# S32R372 register map
Vendor: Freescale Semiconductor, Inc.; Series: Qorivva; File version: 1.6
Registers are 32-bit, read-write, reset 0x0 unless marked. A register's access mark holds for its fields unless they carry their own. Offsets are from the block's base; [hi:lo] are bit positions; {n}, {i} and the like mark numbered series.

## SWT_1 — SWT
Base 0xFC054000; register names take the prefix SWT_1_
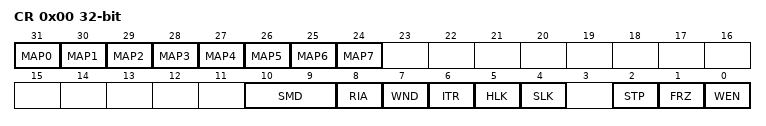
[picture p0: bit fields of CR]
0x00 CR — SWT Control Register
  [31-n] MAP{n} (n=0..7) — Master Access Protection for Master {n}
    0=Access for the master is not enabled; 1=Access for the master is enabled
  [10:9] SMD — Service Mode
    0=Fixed Service Sequence: The watchdog is serviced by writing the fixed sequence 0xA602, 0xB480 to SWT_SR; 1=Keyed Service Sequence: The watchdog is serviced by writing two pseudorandom key values to SWT_SR; 2=Fixed Address Execution: The watchdog is serviced by executing code at the address loaded into the designated IAC register, which cannot be updated while the watchdog is enabled; 3=Incremental Address Execution: The watchdog is serviced by executing code at the address loaded into the designated IAC register, which can be updated
  [8] RIA — Reset on Invalid Access
    0=Invalid access to the SWT generates a bus error; 1=Invalid access to the SWT causes a reset request if WEN is 1
  [7] WND — Window Mode
    0=Regular mode: service sequence can be done at any time; 1=Windowed mode: service sequence is valid only when the down counter is less than the value in the SWT_WN register
  [6] ITR — Interrupt Then Reset
    0=Generate a reset request on a time-out; 1=Generate an interrupt on an initial time-out; generate a reset request on a second consecutive time-out
  [5] HLK — Hard Lock
    0=SWT_CR, SWT_TO, SWT_WN and SWT_SK are read/write registers if SLK is 0; 1=SWT_CR, SWT_TO, SWT_WN and SWT_SK are read-only registers
  [4] SLK — Soft Lock
    0=SWT_CR, SWT_TO, SWT_WN and SWT_SK are read/write registers if HLK is 0; 1=SWT_CR, SWT_TO, SWT_WN and SWT_SK are read-only registers
  [2] STP — Stop Mode Control
    0=SWT counter continues to run in stop mode; 1=SWT counter is stopped in stop mode
  [1] FRZ — Debug Mode Control
    0=SWT counter continues to run in debug mode; 1=SWT counter is stopped in debug mode
  [0] WEN — Watchdog Enabled
    0=SWT is disabled; 1=SWT is enabled
0x04 IR — SWT Interrupt Register
  [0] TIF — Time-out Interrupt Flag
    0=No interrupt request; 1=Interrupt request due to an initial time-out
0x08 TO — SWT Time-out Register
  [31:0] WTO — Watchdog time-out period in clock cycles
0x0C WN — SWT Window Register
  [31:0] WST — Window Start Value
0x10 SR — SWT Service Register
  [15:0] WSC wo — Watchdog Service Code
0x14 CO ro — SWT Counter Output Register
  [31:0] CNT — Watchdog Count
0x18 SK — SWT Service Key Register
  [15:0] SK — Service Key

## SWT_2 — SWT
Base 0xFC058000; register names take the prefix SWT_2_
Registers as SWT_1.

## STM_1 — STM
Base 0xFC06C000; register names take the prefix STM_1_
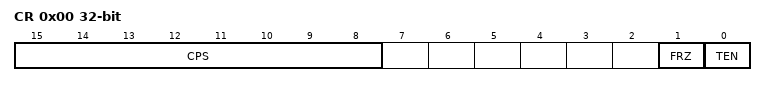
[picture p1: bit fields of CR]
0x00 CR — STM Control Register
  [15:8] CPS — Counter Prescaler.
  [1] FRZ — Freeze.
    0=STM counter continues to run in debug mode; 1=STM counter is stopped in debug mode
  [0] TEN — Timer counter Enabled.
    0=Counter is disabled; 1=Counter is enabled
0x04 CNT — STM Count Register
  [31:0] CNT — Timer count value used as the time base for all channels.
{0x10+0x10*i} CCR{i} (i=0..3) — STM Channel Control Register
  [0] CEN — Channel Enable
    0=The channel is disabled; 1=The channel is enabled
{0x14+0x10*i} CIR{i} (i=0..3) — STM Channel Interrupt Register
  [0] CIF — Channel Interrupt Flag
    0=No interrupt request; 1=Interrupt request due to a match on the channel
{0x18+0x10*i} CMP{i} (i=0..3) — STM Channel Compare Register
  [31:0] CMP — Compare value for channel n.

## STM_2 — STM
Base 0xFC070000; register names take the prefix STM_2_
Registers as STM_1.

## CSE
Base 0xFC074000; register names take the prefix CSE_
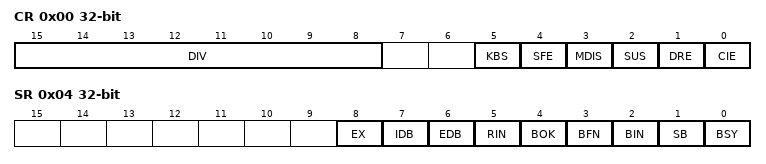
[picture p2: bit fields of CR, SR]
0x00 CR — CSE Control Register
  [15:8] DIV — TRNG Clock Divider Select
  [5] KBS — Key Bank Select. Selects which set of application keys are visible for commands. See .
    0=Select KEY_1-KEY_10; 1=Select KEY_11-KEY_20
  [4] SFE — Security Flag Extension
    0=Security Flag Extension disabled; 1=Security Flag Extension enabled
  [3] MDIS — Module Disable
    0=Normal mode; 1=Low-power mode
  [2] SUS — Suspend Command Processing
    0=Enable processing of commands; 1=Suspend command processing
  [1] DRE — DMA Request Enable
    0=DMA request not enabled; 1=DMA request enabled
  [0] CIE — Command Complete Interrupt Enable
    0=Command Complete Interrupt disabled; 1=Command Complete Interrupt enabled
0x04 SR ro — CSE Status Register
  [8] EX — Execute. Ignore the status of CSE_SR[EX] when CSE_SR[BSY] flag is '0'.
    0=Command processor is idle or suspended; 1=Command processor is executing a command
  [7] IDB — Internal Debug
    0=Internal Debug functions disabled; 1=Internal Debug functions enabled
  [6] EDB — External Debug. The EDB bit is set when the CPU debug port is activated and is cleared on reset.
    0=External debugger not attached; 1=External debugger attached
  [5] RIN — Random Number Generator Initialized
    0=Random number generator not initialized; 1=Random number generator initialized
  [4] BOK — Secure Boot OK
    0=Secure boot not completed or secure boot failure; 1=Secure boot successful
  [3] BFN — Secure Boot Finished
    0=Secure boot not finished; 1=Secure boot finished
  [2] BIN — Secure Boot Initialization
    0=Secure boot personalization not completed; 1=Secure boot personalization completed
  [1] SB — Secure Boot
    0=Secure boot not activated; 1=Secure boot activated
  [0] BSY — Busy. The BSY bit is set when a command is issued and cleared when command processing is completed.
    0=Command processing completed; 1=Command processing not completed
0x08 IR — CSE Interrupt Register
  [0] CIF — Command Complete Interrupt Flag
    0=Command not complete; 1=Command completed
0x0C ECR ro — CSE Error Code Register
  [4:0] EC — Error Code from the last command completed
0x20 CMD — CSE Command Register
  [4:0] CMD — Command
{0x20+4i} P{i} (i=1..5) — CSE Parameter Register
  [31:0] PARM — Command parameter (data value or address of data value).
